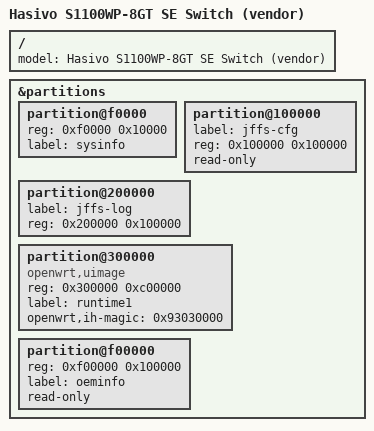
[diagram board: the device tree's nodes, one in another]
// SPDX-License-Identifier: (GPL-2.0-or-later OR MIT)
/dts-v1/;

#include "rtl9303_hasivo_s1100wp-8gt-se.dts"

/ {
	model = "Hasivo S1100WP-8GT SE Switch (vendor)";
};

&partitions {
	/delete-node/ partition@f0000;

	partition@f0000 {
		reg = <0xf0000 0x10000>;
		label = "sysinfo";
	};

	partition@100000 {
		label = "jffs-cfg";
		reg = <0x100000 0x100000>;
		read-only;
	};

	partition@200000 {
		label = "jffs-log";
		reg = <0x200000 0x100000>;
	};

	partition@300000 {
		reg = <0x300000 0xc00000>;
		compatible = "openwrt,uimage", "denx, uimage";
		label = "runtime1";
		openwrt,ih-magic = <0x93030000>;
	};

	partition@f00000 {
		reg = <0xf00000 0x100000>;
		label = "oeminfo";
		read-only;
	};
};
